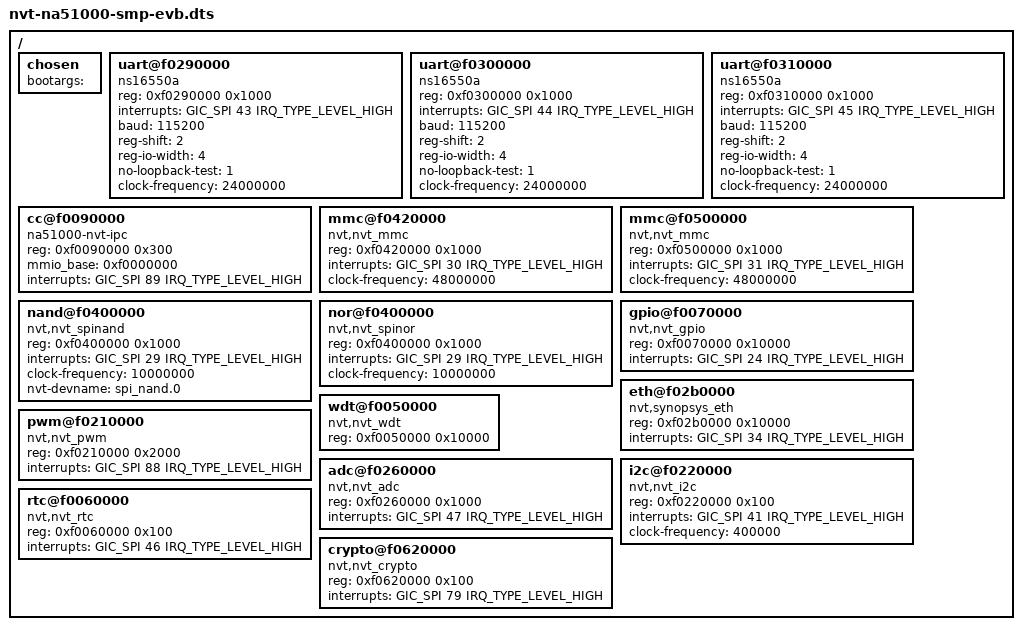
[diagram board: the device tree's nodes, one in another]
/*
 * Novatek Ltd. NA51000 BSP part of dts
 *
 * Cortex-A53 MPCore
 *
 */

/dts-v1/;

#include "nvt-na51000-basic.dtsi"

/ {
	chosen {
		bootargs = " ";
	};

	uart@f0290000 {
		compatible = "ns16550a";
		reg = <0xf0290000 0x1000>;
		interrupts = <GIC_SPI 43 IRQ_TYPE_LEVEL_HIGH>;
		baud = <115200>;
		reg-shift = <2>;
		reg-io-width = <4>;
		no-loopback-test = <1>;
		clock-frequency = <24000000>;
	};

	uart@f0300000 {
		compatible = "ns16550a";
		reg = <0xf0300000 0x1000>;
		interrupts = <GIC_SPI 44 IRQ_TYPE_LEVEL_HIGH>;
		baud = <115200>;
		reg-shift = <2>;
		reg-io-width = <4>;
		no-loopback-test = <1>;
		clock-frequency = <24000000>;
	};

	uart@f0310000 {
		compatible = "ns16550a";
		reg = <0xf0310000 0x1000>;
		interrupts = <GIC_SPI 45 IRQ_TYPE_LEVEL_HIGH>;
		baud = <115200>;
		reg-shift = <2>;
		reg-io-width = <4>;
		no-loopback-test = <1>;
		clock-frequency = <24000000>;
	};

	cc@f0090000 {
		compatible = "na51000-nvt-ipc";
		reg = <0xf0090000 0x300>;
		mmio_base  = <0xf0000000>;
		interrupts = <GIC_SPI 89 IRQ_TYPE_LEVEL_HIGH>;
	};

	mmc@f0420000 {
		compatible = "nvt,nvt_mmc";
		reg = <0xf0420000 0x1000>;
		interrupts = <GIC_SPI 30 IRQ_TYPE_LEVEL_HIGH>;
		clock-frequency = <48000000>;
	};

	mmc@f0500000 {
		compatible = "nvt,nvt_mmc";
		reg = <0xf0500000 0x1000>;
		interrupts = <GIC_SPI 31 IRQ_TYPE_LEVEL_HIGH>;
		clock-frequency = <48000000>;
	};


	nand@f0400000 {
		compatible = "nvt,nvt_spinand";
		reg = <0xf0400000 0x1000>;
		interrupts = <GIC_SPI 29 IRQ_TYPE_LEVEL_HIGH>;
		clock-frequency = <10000000>;
		nvt-devname = "spi_nand.0";
	};

	nor@f0400000 {
		compatible = "nvt,nvt_spinor";
		reg = <0xf0400000 0x1000>;
		interrupts = <GIC_SPI 29 IRQ_TYPE_LEVEL_HIGH>;
		clock-frequency = <10000000>;
	};

        gpio@f0070000 {
		compatible = "nvt,nvt_gpio";
		reg = <0xf0070000 0x10000>;
		interrupts = <GIC_SPI 24 IRQ_TYPE_LEVEL_HIGH>;
        };

	eth@f02b0000 {
		compatible = "nvt,synopsys_eth";
		reg = <0xf02b0000 0x10000>;
		interrupts = <GIC_SPI 34 IRQ_TYPE_LEVEL_HIGH>;
	};

	wdt@f0050000 {
		compatible = "nvt,nvt_wdt";
		reg = <0xf0050000 0x10000>;
	};

	pwm@f0210000 {
		compatible = "nvt,nvt_pwm";
		reg = <0xf0210000 0x2000>;
		interrupts = <GIC_SPI 88 IRQ_TYPE_LEVEL_HIGH>;
	};

	adc@f0260000 {
		compatible = "nvt,nvt_adc";
		reg = <0xf0260000 0x1000>;
		interrupts = <GIC_SPI 47 IRQ_TYPE_LEVEL_HIGH>;
	};

	i2c@f0220000 {
		compatible = "nvt,nvt_i2c";
		reg = <0xf0220000 0x100>;
		interrupts = <GIC_SPI 41 IRQ_TYPE_LEVEL_HIGH>;
		clock-frequency = <400000>;
	};

	rtc@f0060000 {
		compatible = "nvt,nvt_rtc";
		reg = <0xf0060000 0x100>;
		interrupts = <GIC_SPI 46 IRQ_TYPE_LEVEL_HIGH>;
	};

	crypto@f0620000 {
		compatible = "nvt,nvt_crypto";
		reg = <0xf0620000 0x100>;
		interrupts = <GIC_SPI 79 IRQ_TYPE_LEVEL_HIGH>;
	};
};
